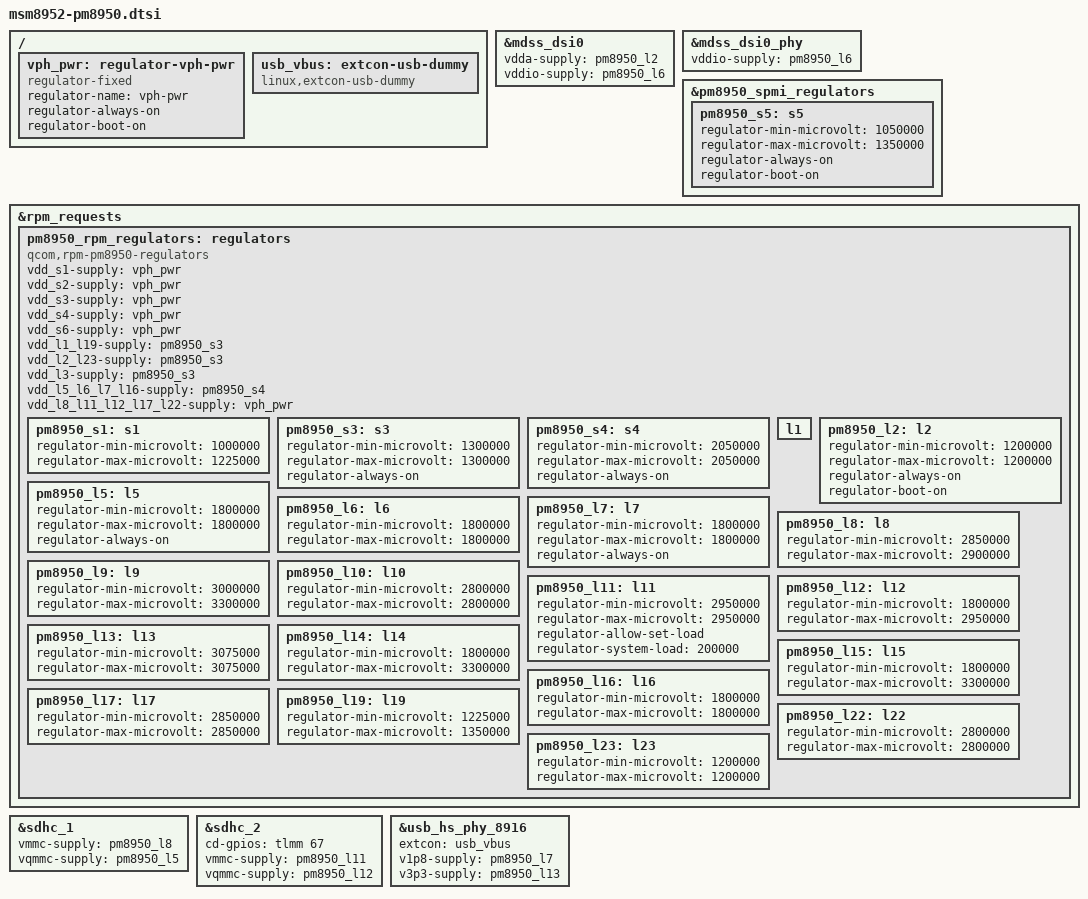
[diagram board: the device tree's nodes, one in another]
// SPDX-License-Identifier: GPL-2.0-only
/*
 * Do not trust any value written in here, I just added this to make a little bit generalization.
 * I am not responsible for any damage caused by that.
 */

#include "msm8952.dtsi"
#include "pm8950.dtsi"
#include <dt-bindings/gpio/gpio.h>

/ {
	vph_pwr: regulator-vph-pwr {
		compatible = "regulator-fixed";
		regulator-name = "vph-pwr";
		regulator-always-on;
		regulator-boot-on;
	};

	usb_vbus: extcon-usb-dummy {
		compatible = "linux,extcon-usb-dummy";
	};
};

&mdss_dsi0 {
	vdda-supply = <&pm8950_l2>;
	vddio-supply = <&pm8950_l6>;
};

&mdss_dsi0_phy {
	vddio-supply = <&pm8950_l6>;
};

&pm8950_spmi_regulators {
	// PM8950 S5 + S6 = VDD_APC supply
	pm8950_s5: s5 {
		regulator-min-microvolt = <1050000>;
		regulator-max-microvolt = <1350000>;
		regulator-always-on;
		regulator-boot-on;
	};
};

&rpm_requests {
	pm8950_rpm_regulators: regulators {
		compatible = "qcom,rpm-pm8950-regulators";
		vdd_s1-supply = <&vph_pwr>;
		vdd_s2-supply = <&vph_pwr>;
		vdd_s3-supply = <&vph_pwr>;
		vdd_s4-supply = <&vph_pwr>;
		vdd_s6-supply = <&vph_pwr>;
		vdd_l1_l19-supply = <&pm8950_s3>;
		vdd_l2_l23-supply = <&pm8950_s3>;
		vdd_l3-supply = <&pm8950_s3>;
		vdd_l5_l6_l7_l16-supply = <&pm8950_s4>;
		vdd_l8_l11_l12_l17_l22-supply = <&vph_pwr>;

		pm8950_s1: s1 {
			regulator-min-microvolt = <1000000>;
			regulator-max-microvolt = <1225000>;
		};

		pm8950_s3: s3 {
			regulator-min-microvolt = <1300000>;
			regulator-max-microvolt = <1300000>;
			regulator-always-on;
		};
		pm8950_s4: s4 {
			regulator-min-microvolt = <2050000>;
			regulator-max-microvolt = <2050000>;
			regulator-always-on;
		};

		l1 {};

		pm8950_l2: l2 {
			regulator-min-microvolt = <1200000>;
			regulator-max-microvolt = <1200000>;
			regulator-always-on;
			regulator-boot-on;
		};

		/* pm8950_l3 is managed by rpmpd (RPMPD_VDDMX) */

		pm8950_l5: l5 {
			regulator-min-microvolt = <1800000>;
			regulator-max-microvolt = <1800000>;
			regulator-always-on;
		};

		pm8950_l6: l6 {
			regulator-min-microvolt = <1800000>;
			regulator-max-microvolt = <1800000>;
		};

		pm8950_l7: l7 {
			regulator-min-microvolt = <1800000>;
			regulator-max-microvolt = <1800000>;
			regulator-always-on;
		};

		pm8950_l8: l8 {
			regulator-min-microvolt = <2850000>;
			regulator-max-microvolt = <2900000>;
		};

		pm8950_l9: l9 {
			regulator-min-microvolt = <3000000>;
			regulator-max-microvolt = <3300000>;
		};

		pm8950_l10: l10 {
			regulator-min-microvolt = <2800000>;
			regulator-max-microvolt = <2800000>;
		};

		pm8950_l11: l11 {
			regulator-min-microvolt = <2950000>;
			regulator-max-microvolt = <2950000>;
			regulator-allow-set-load;
			regulator-system-load = <200000>;
		};

		pm8950_l12: l12 {
			regulator-min-microvolt = <1800000>;
			regulator-max-microvolt = <2950000>;
		};

		pm8950_l13: l13 {
			regulator-min-microvolt = <3075000>;
			regulator-max-microvolt = <3075000>;
		};

		pm8950_l14: l14 {
			regulator-min-microvolt = <1800000>;
			regulator-max-microvolt = <3300000>;
		};

		pm8950_l15: l15 {
			regulator-min-microvolt = <1800000>;
			regulator-max-microvolt = <3300000>;
		};

		pm8950_l16: l16 {
			regulator-min-microvolt = <1800000>;
			regulator-max-microvolt = <1800000>;
		};

		pm8950_l17: l17 {
			regulator-min-microvolt = <2850000>;
			regulator-max-microvolt = <2850000>;
		};

		pm8950_l19: l19 {
			regulator-min-microvolt = <1225000>;
			regulator-max-microvolt = <1350000>;
		};

		pm8950_l22: l22 {
			regulator-min-microvolt = <2800000>;
			regulator-max-microvolt = <2800000>;
		};

		pm8950_l23: l23 {
			regulator-min-microvolt = <1200000>;
			regulator-max-microvolt = <1200000>;
		};
	};
};

&sdhc_1 {
	vmmc-supply = <&pm8950_l8>;
	vqmmc-supply = <&pm8950_l5>;
};

&sdhc_2 {
	cd-gpios = <&tlmm 67 GPIO_ACTIVE_HIGH>;
	vmmc-supply = <&pm8950_l11>;
	vqmmc-supply = <&pm8950_l12>;
};

&usb_hs_phy_8916 {
	extcon = <&usb_vbus>;
//	vdd-supply = <&pm8950_l2>;
	v1p8-supply = <&pm8950_l7>;
	v3p3-supply = <&pm8950_l13>;
};
